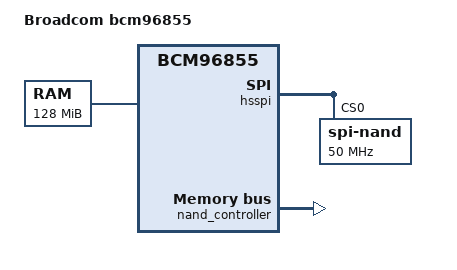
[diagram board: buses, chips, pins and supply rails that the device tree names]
// SPDX-License-Identifier: GPL-2.0+
/*
 * Copyright 2019 Broadcom Ltd.
 */


/dts-v1/;

#include "bcm6855.dtsi"

/ {
	model = "Broadcom bcm96855";
	compatible = "broadcom,bcm96855", "brcm,bcm96855";

	aliases {
		serial0 = &uart0;
	};

	chosen {
		stdout-path = "serial0:115200n8";
	};

	memory {
		device_type = "memory";
		reg = <0x0 0x08000000>;
	};
};

&hsspi {
	status = "okay";
	spi-nand {
		compatible = "spi-nand";
		reg = <0>;
		#address-cells = <1>;
		#size-cells = <0>;
		bootph-all;
		spi-max-frequency = <50000000>;
	};
};

&nand_controller {
	brcm,wp-not-connected;
	status = "okay";
};

&nandcs {
	nand-on-flash-bbt;
	brcm,nand-ecc-use-strap;
};
